# NUC1311AE_v1 register map
File version: 1.0
Registers are 32-bit, read-write, reset 0x0 unless marked. A register's access mark holds for its fields unless they carry their own. Offsets are from the block's base; [hi:lo] are bit positions; {n}, {i} and the like mark numbered series; 'fields as' and 'values as' point back to an identical list.

## CLK — CLK Register Map
Base 0x50000200
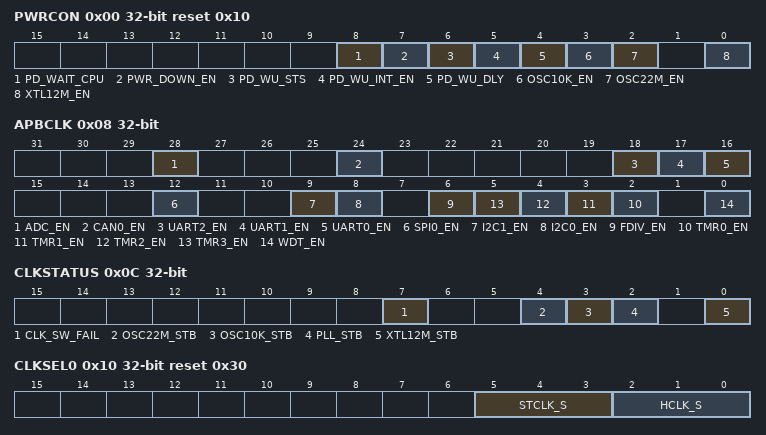
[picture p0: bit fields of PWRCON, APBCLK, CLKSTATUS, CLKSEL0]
0x00 PWRCON reset 0x10 (reset mask 0xFFFFFFF0) — System Power-down Control Register
  [8] PD_WAIT_CPU — Power-Down Entry Condition Control (Write Protect). Note: This bit is the protected bit, and programming it needs to write '59h', '16h', and '88h' to address 0x5000_0100 to disable register protection. Refer to the register REGWRPROT at address GCR_BA+0x100.
    0=Chip enters Power-down mode when the PWR_DOWN_EN bit is set to 1; 1=Chip enters Power- down mode when the both PD_WAIT_CPU and PWR_DOWN_EN bits are set to 1 and CPU runs WFI instruction
  [7] PWR_DOWN_EN — System Power-Down Enable Control (Write Protect). When this bit is set to 1, Power-down mode is enabled and chip Power-down behavior will depends on the PD_WAIT_CPU bit (a) If the PD_WAIT_CPU is 0, the chip enters Power-down mode immediately after the PWR_DOWN_EN bit set. (b) if the PD_WAIT_CPU is 1, the chip keeps active till the CPU sleep mode is also active and then the chip enters Power-down mode (recommend). When chip wakes up from Power-down mode, this bit is cleared by hardware. User needs to set this bit again for next Power-down. In Power-down mode, 4~24 MHz external high speed crystal oscillator (HXT) and the 22.1184 MHz internal high speed RC oscillator (HIRC) will be disabled in this mode, but the 10 kHz internal low speed RC oscillator (LIRC) is not controlled by Power-down mode. In Power- down mode, the PLL and system clock are disabled, and ignored the clock source selection. The clocks of peripheral are not controlled by Power-down mode, if the peripheral clock source is from the 10 kHz internal low speed RC oscillator (LIRC). Note: This bit is the protected bit, and programming it needs to write '59h', '16h', and '88h' to address 0x5000_0100 to disable register protection. Refer to the register REGWRPROT at address GCR_BA+0x100.
    0=Chip operating normally or chip in Idle mode because of WFI command; 1=Chip enters Power-down mode instantly or waits CPU sleep command WFI
  [6] PD_WU_STS — Power-Down Mode Wake-Up Interrupt Status. Set by 'Power-down wake-up event', it indicates that resume from Power-down mode'. The flag is set if the GPIO, UART, WDT, I2C, TIMER, CAN, or BOD wake-up occurred. Write 1 to clear the bit to 0. Note: This bit is working only if PD_WU_INT_EN (PWRCON[5]) set to 1.
  [5] PD_WU_INT_EN — Power-Down Mode Wake-Up Interrupt Enable Control (Write Protect). Note1: The interrupt will occur when both PD_WU_STS and PD_WU_INT_EN are high. Note2: This bit is the protected bit, and programming it needs to write '59h', '16h', and '88h' to address 0x5000_0100 to disable register protection. Refer to the register REGWRPROT at address GCR_BA+0x100.
    0=Power-down mode wake-up interrupt Disabled; 1=Power-down mode wake-up interrupt Enabled
  [4] PD_WU_DLY — Wake-Up Delay Counter Enable Control (Write Protect). When the chip wakes up from Power-down mode, the clock control will delay certain clock cycles to wait system clock stable. The delayed clock cycle is 4096 clock cycles when chip works at 4~24 MHz external high speed crystal oscillator (HXT), and 256 clock cycles when chip works at 22.1184 MHz internal high speed oscillator (HIRC). Note: This bit is the protected bit, and programming it needs to write '59h', '16h', and '88h' to address 0x5000_0100 to disable register protection. Refer to the register REGWRPROT at address GCR_BA+0x100.
    0=Clock cycles delay Disabled; 1=Clock cycles delay Enabled
  [3] OSC10K_EN — 10 KHz Internal Low Speed RC Oscillator (LIRC) Enable Control (Write Protect). Note: This bit is the protected bit, and programming it needs to write '59h', '16h', and '88h' to address 0x5000_0100 to disable register protection. Refer to the register REGWRPROT at address GCR_BA+0x100.
    0=10 kHz internal low speed RC oscillator (LIRC) Disabled; 1=10 kHz internal low speed RC oscillator (LIRC) Enabled
  [2] OSC22M_EN — 22.1184 MHz Internal High Speed RC Oscillator (HIRC) Enable Control (Write Protect). Note: This bit is the protected bit, and programming it needs to write '59h', '16h', and '88h' to address 0x5000_0100 to disable register protection. Refer to the register REGWRPROT at address GCR_BA+0x100.
    0=22.1184 MHz internal high speed RC oscillator (HIRC) Disabled; 1=22.1184 MHz internal high speed RC oscillator (HIRC) Enabled
  [0] XTL12M_EN — 4~24 MHz External High Speed Crystal Oscillator (HXT) Enable Control (Write Protect). The bit default value is set by flash controller user configuration register CONFIG0 [26:24]. When the default clock source is from 4~24 MHz external high speed crystal oscillator, this bit is set to 1 automatically. Note: This bit is the protected bit, and programming it needs to write '59h', '16h', and '88h' to address 0x5000_0100 to disable register protection. Refer to the register REGWRPROT at address GCR_BA+0x100.
    0=4 ~ 24 MHz external high speed crystal oscillator (HXT) Disabled; 1=4 ~ 24 MHz external high speed crystal oscillator (HXT) Enabled
0x04 AHBCLK reset 0x5 — AHB Devices Clock Enable Control Register
  [2] ISP_EN — Flash ISP Controller Clock Enable Control
    0=Flash ISP peripherial clock Disabled; 1=Flash ISP peripherial clock Enabled
0x08 APBCLK (reset mask 0xFFFFFFF0) — APB Devices Clock Enable Control Register
  [28] ADC_EN — Analog-Digital-Converter (ADC) Clock Enable Control
    0=ADC clock Disabled; 1=ADC clock Enabled
  [24] CAN0_EN — CAN Bus Controller-0 Clock Enable Control
    0=CAN0 clock Disabled; 1=CAN0 clock Enabled
  [18] UART2_EN — UART2 Clock Enable Control
    0=UART2 clock Disabled; 1=UART2 clock Enabled
  [17] UART1_EN — UART1 Clock Enable Control
    0=UART1 clock Disabled; 1=UART1 clock Enabled
  [16] UART0_EN — UART0 Clock Enable Control
    0=UART0 clock Disabled; 1=UART0 clock Enabled
  [12] SPI0_EN — SPI0 Clock Enable Control
    0=SPI0 clock Disabled; 1=SPI0 clock Enabled
  [9] I2C1_EN — I2C1 Clock Enable Control
    0=I2C1 clock Disabled; 1=I2C1 clock Enabled
  [8] I2C0_EN — I2C0 Clock Enable Control
    0=I2C0 clock Disabled; 1=I2C0 clock Enabled
  [6] FDIV_EN — Frequency Divider Output Clock Enable Control
    0=FDIV clock Disabled; 1=FDIV clock Enabled
  [n+2] TMR{n}_EN (n=0..3) — Timer{n} Clock Enable Control
    0=Timer{n} clock Disabled; 1=Timer{n} clock Enabled
  [0] WDT_EN — Watchdog Timer Clock Enable Control (Write Protect). Note: This bit is the protected bit, and programming it needs to write '59h', '16h', and '88h' to address 0x5000_0100 to disable register protection. Refer to the register REGWRPROT at address GCR_BA+0x100.
    0=Watchdog Timer clock Disabled; 1=Watchdog Timer clock Enabled
0x0C CLKSTATUS (reset mask 0xFFFFFF00) — Clock Status Monitor Register
  [7] CLK_SW_FAIL ro — Clock Switching Fail Flag (Read Only). This bit is an index that if current system clock source is match as user defined at HCLK_S (CLKSEL[2:0]). When user switchs system clock, the system clock source will keep old clock until the new clock is stable. During the period that waiting new clock stable, this bit will be an index shows system clock source is not match as user wanted.
    0=Clock switching success; 1=Clock switching failure
  [4] OSC22M_STB ro — 22.1184 MHz Internal High Speed RC Oscillator (HIRC) Clock Source Stable Flag (Read Only)
    0=22.1184 MHz internal high speed RC oscillator (HIRC) clock is not stable or disabled; 1=22.1184 MHz internal high speed RC oscillator (HIRC) clock is stable and enabled
  [3] OSC10K_STB ro — Internal 10 KHz Low Speed Oscillator (LIRC) Clock Source Stable Flag (Read Only)
    0=10 kHz internal low speed RC oscillator (LIRC) clock is not stable or disabled; 1=10 kHz internal low speed RC oscillator (LIRC) clock is stable and enabled
  [2] PLL_STB ro — Internal PLL Clock Source Stable Flag (Read Only)
    0=Internal PLL clock is not stable or disabled; 1=Internal PLL clock is stable in normal mode
  [0] XTL12M_STB ro — 4~24 MHz External High Speed Crystal Oscillator (HXT) Clock Source Stable Flag (Read Only)
    0=4~24 MHz external high speed crystal oscillator (HXT) clock is not stable or disabled; 1=4~24 MHz external high speed crystal oscillator (HXT) clock is stable and enabled
0x10 CLKSEL0 reset 0x30 (reset mask 0xFFFFFFF0) — Clock Source Select Control Register 0
  [5:3] STCLK_S — Cortex-M0 SysTick Clock Source Select (Write Protect)
    0=Clock source from 4~24 MHz external high speed crystal oscillator (HXT); 2=Clock source from 4~24 MHz external high speed crystal oscillator (HXT)/2; 3=Clock source from HCLK/2; 7=Clock source from 22.1184 MHz internal high speed RC oscillator (HIRC)/2
  [2:0] HCLK_S — HCLK Clock Source Select (Write Protect). Before clock switching, the related clock sources (both pre-select and new-select) must be enabled. The 3-bit default value is reloaded from the value of CFOSC (CONFIG0[26:24]) in user configuration register of Flash controller by any reset. Therefore the default value is either 000b or 111b. These bits are protected bit. It means programming this bit needs to write '59h', '16h', '88h' to address 0x5000_0100 to disable register protection. Refer to the register REGWRPROT at address GCR_BA+0x100. Note: This bit is the protected bit, and programming it needs to write '59h', '16h', and '88h' to address 0x5000_0100 to disable register protection. Refer to the register REGWRPROT at address GCR_BA+0x100.
    0=Clock source from 4~24 MHz external high speed crystal oscillator (HXT); 2=Clock source from PLL; 3=Clock source from 10 kHz internal low speed RC oscillator (LIRC); 7=Clock source from 22.1184 MHz internalhigh speed RC oscillator (HIRC)
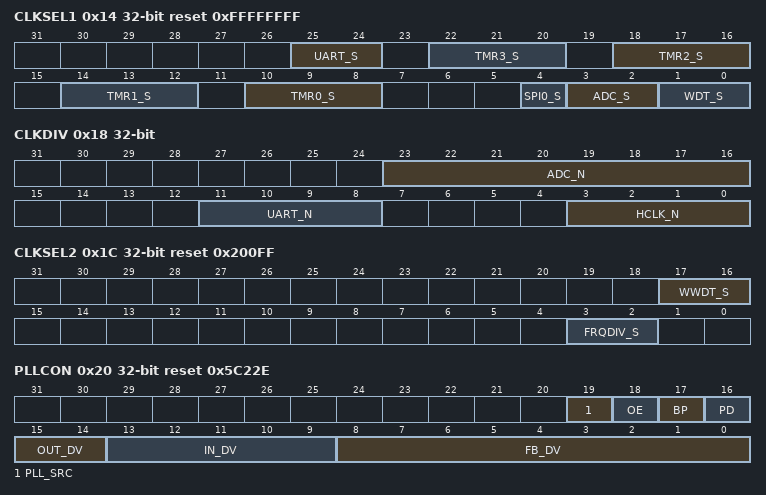
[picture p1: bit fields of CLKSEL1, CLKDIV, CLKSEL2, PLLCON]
0x14 CLKSEL1 reset 0xFFFFFFFF — Clock Source Select Control Register 1
  [25:24] UART_S — UART Clock Source Selection
    0=Clock source from 4~24 MHz external high speed crystal oscillator (HXT); 1=Clock source from PLL; 3=Clock source from 22.1184 MHz internal high speed RC oscillator (HIRC)
  [22:20] TMR3_S — TIMER3 Clock Source Selection
    0=Clock source from 4~24 MHz external high speed crystal oscillator (HXT); 2=Clock source from HCLK; 3=Clock source from external trigger; 5=Clock source from 10 kHz internal low speed RC oscillator (LIRC); 7=Clock source from 22.1184 MHz internal high speed RC oscillator (HIRC)
  [18:16] TMR2_S — TIMER2 Clock Source Selection
    0=Clock source from external 4~24 MHz high speed crystal oscillator (HXT); 2=Clock source from HCLK; 3=Clock source from external trigger; 5=Clock source from 10 kHz internal low speed RC oscillator (LIRC); 7=Clock source from 22.1184 MHz internal high speed RC oscillator (HIRC)
  [14:12] TMR1_S — TIMER1 Clock Source Selection
    values as TMR3_S
  [10:8] TMR0_S — TIMER0 Clock Source Selection
    values as TMR3_S
  [4] SPI0_S — SPI0 Clock Source Selection
    0=Clock source from PLL; 1=Clock source from HCLK
  [3:2] ADC_S — ADC Clock Source Select
    0=Clock source from 4~24 MHz external high speed crystal oscillator (HXT); 1=Clock source from PLL; 2=Clock source from HCLK; 3=Clock source from 22.1184 MHz internal high speed RC oscillator (HIRC)
  [1:0] WDT_S — Watchdog Timer Clock Source Select (Write Protect). Note: This bit is the protected bit, and programming it needs to write '59h', '16h', and '88h' to address 0x5000_0100 to disable register protection. Refer to the register REGWRPROT at address GCR_BA+0x100.
    2=Clock source from HCLK/2048; 3=Clock source from 10 kHz internal low speed RC oscillator (LIRC)
0x18 CLKDIV — Clock Divider Number Register
  [23:16] ADC_N — ADC Clock Divide Number From ADC Clock Source
  [11:8] UART_N — UART Clock Divide Number From UART Clock Source
  [3:0] HCLK_N — HCLK Clock Divide Number From HCLK Clock Source
0x1C CLKSEL2 reset 0x200FF — Clock Source Select Control Register 2
  [17:16] WWDT_S — Window Watchdog Timer Clock Source Selection
    2=Clock source from HCLK/2048 clock; 3=Clock source from 10 kHz internal low speed RC oscillator clock
  [3:2] FRQDIV_S — Clock Divider Clock Source Selection
    0=Clock source from 4~24 MHz external high speed crystal oscillator clock; 2=Clock source from HCLK; 3=Clock source from 22.1184 MHz internal high speed RC oscillator clock
0x20 PLLCON reset 0x5C22E — PLL Control Register
  [19] PLL_SRC — PLL Source Clock Selection
    0=PLL source clock from 4~24 MHz external high speed crystal oscillator; 1=PLL source clock from 22.1184 MHz internal high speed RC oscillator
  [18] OE — PLL OE (FOUT Enable) Pin Control
    0=PLL FOUT Enabled; 1=PLL FOUT is fixed low
  [17] BP — PLL Bypass Control
    0=PLL is in Normal mode (default); 1=PLL clock output is same as PLL source clock input
  [16] PD — Power-Down Mode. If the PWR_DOWN_EN bit is set to 1 in PWRCON register, the PLL will enter Power-down mode too.
    0=PLL is in Normal mode; 1=PLL is in Power-down mode (default)
  [15:14] OUT_DV — PLL Output Divider Control Bits. Refer to the formulas below the table.
  [13:9] IN_DV — PLL Input Divider Control Bits. Refer to the formulas below the table.
  [8:0] FB_DV — PLL Feedback Divider Control Bits. Refer to the formulas below the table.
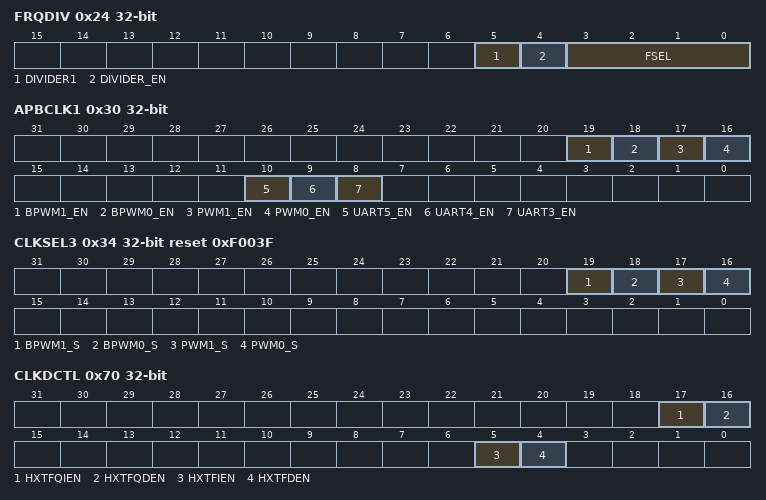
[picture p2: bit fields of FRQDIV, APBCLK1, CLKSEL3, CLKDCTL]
0x24 FRQDIV — Frequency Divider Control Register
  [5] DIVIDER1 — Frequency Divider One Enable Control
    0=Frequency divider will output clock with source frequency divided by FSEL; 1=Frequency divider will output clock with source frequency
  [4] DIVIDER_EN — Frequency Divider Enable Control
    0=Frequency divider function Disabled; 1=Frequency divider function Enabled
  [3:0] FSEL — Divider Output Frequency Selection Bits. The formula of output frequency is. Fin is the input clock frequency. Fout is the frequency of divider output clock. N is the 4-bit value of FSEL[3:0].
0x30 APBCLK1 — APB Devices Clock Enable Control Register 1
  [19] BPWM1_EN — BPWM1 Clock Enable Control
    0=BPWM1 clock Disabled; 1=BPWM1 clock Enabled
  [18] BPWM0_EN — BPWM0 Clock Enable Control
    0=BPWM0 clock Disabled; 1=BPWM0 clock Enabled
  [17] PWM1_EN — PWM1 Clock Enable Control
    0=PWM1 clock Disabled; 1=PWM1 clock Enabled
  [16] PWM0_EN — PWM0 Clock Enable Control
    0=PWM0 clock Disabled; 1=PWM0 clock Enabled
  [10] UART5_EN — UART5 Clock Enable Control
    0=UART5 clock Disabled; 1=UART5 clock Enabled
  [9] UART4_EN — UART4 Clock Enable Control
    0=UART4 clock Disabled; 1=UART4 clock Enabled
  [8] UART3_EN — UART3 Clock Enable Control
    0=UART3 clock Disabled; 1=UART3 clock Enabled
0x34 CLKSEL3 reset 0xF003F — Clock Source Select Control Register 3
  [all] fields
    0=Clock source from PLL; 1=Clock source from PCLK
  [19] BPWM1_S — BPWM1 Clock Source Selection. The Engine clock source of BPWM1 is defined by BPWM1_S.
  [18] BPWM0_S — BPWM0 Clock Source Selection. The Engine clock source of BPWM0 is defined by BPWM0_S.
  [17] PWM1_S — PWM1 Clock Source Selection. The Engine clock source of PWM1 is defined by PWM1_S.
  [16] PWM0_S — PWM0 Clock Source Selection. The Engine clock source of PWM0 is defined by PWM0_S.
0x70 CLKDCTL — Clock Fail Detector Control Register
  [17] HXTFQIEN — HXT Clock Frequency Monitor Interrupt Enable Control
    0=HXT clock frequency monitor fail interrupt Disabled; 1=HXT clock frequency monitor fail interrupt Enabled
  [16] HXTFQDEN — HXT Clock Frequency Monitor Enable Control
    0=HXT clock frequency monitor Disabled; 1=HXT clock frequency monitor Enabled
  [5] HXTFIEN — HXT Clock Fail Interrupt Enable Control
    0=HXT clock Fail interrupt Disabled; 1=HXT clock Fail interrupt Enabled
  [4] HXTFDEN — HXT Clock Fail Detector Enable Control
    0=HXT clock Fail detector Disabled; 1=HXT clock Fail detector Enabled
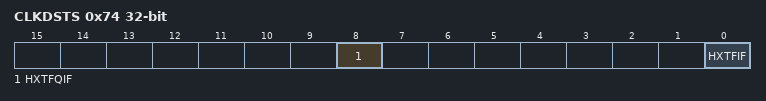
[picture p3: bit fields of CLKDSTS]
0x74 CLKDSTS — Clock Fail Detector Status Register
  [8] HXTFQIF — HXT Clock Frequency Monitor Interrupt Flag
    0=HXT clock normal; 1=HXT clock frequency abnormal (write '1' to clear)
  [0] HXTFIF — HXT Clock Fail Interrupt Flag
    0=HXT clock normal; 1=HXT clock stop (write '1' to clear)
0x78 CDUPB — Clock Frequency Detector Upper Boundary Register
  [9:0] UPERBD — HXT Clock Frequency Detector Upper Boundary. The bits define the high value of frequency monitor window. When HXT frequency monitor value higher than this register, the HXT frequency detect fail interrupt flag will set to 1.
0x7C CDLOWB — Clock Frequency Detector Lower Boundary Register
  [9:0] LOWERBD — HXT Clock Frequency Detector Lower Boundary. The bits define the low value of frequency monitor window. When HXT frequency monitor values lower than this register, the HXT frequency detect fail interrupt flag will set to 1.
